VERSION ""

NS_ :

BS_:

BU_: Vector__XXX

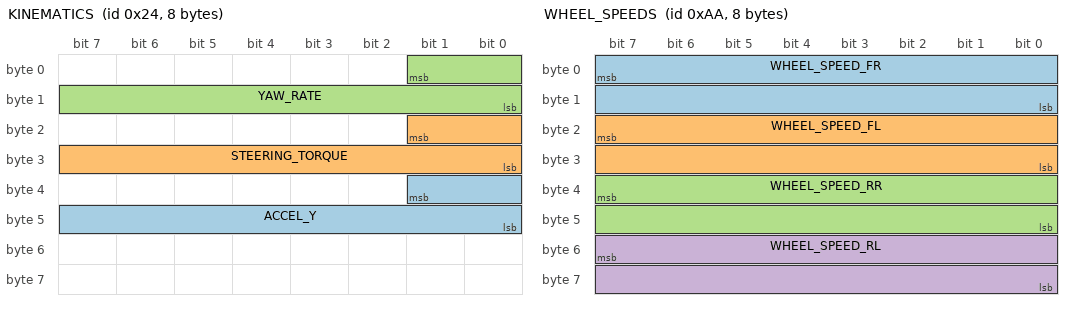
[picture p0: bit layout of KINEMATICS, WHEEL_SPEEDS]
BO_ 36 KINEMATICS: 8 Vector__XXX
SG_ ACCEL_Y : 33|10@0+ (1,-512) [0|511] "" Vector__XXX
SG_ STEERING_TORQUE : 17|10@0+ (1,-512) [0|511] "" Vector__XXX
SG_ YAW_RATE : 1|10@0+ (1,-512) [0|511] "" Vector__XXX

BO_ 166 BRAKE: 8 Vector__XXX
SG_ BRAKE_AMOUNT : 7|8@0+ (1,0) [0|255] "" Vector__XXX
SG_ BRAKE_PEDAL : 23|8@0+ (1,0) [0|255] "" Vector__XXX

BO_ 170 WHEEL_SPEEDS: 8 Vector__XXX
SG_ WHEEL_SPEED_FR : 7|16@0+ (0.0062,-67.67) [0|250] "mph" Vector__XXX
SG_ WHEEL_SPEED_FL : 23|16@0+ (0.0062,-67.67) [0|250] "mph" Vector__XXX
SG_ WHEEL_SPEED_RR : 39|16@0+ (0.0062,-67.67) [0|250] "mph" Vector__XXX
SG_ WHEEL_SPEED_RL : 55|16@0+ (0.0062,-67.67) [0|250] "mph" Vector__XXX

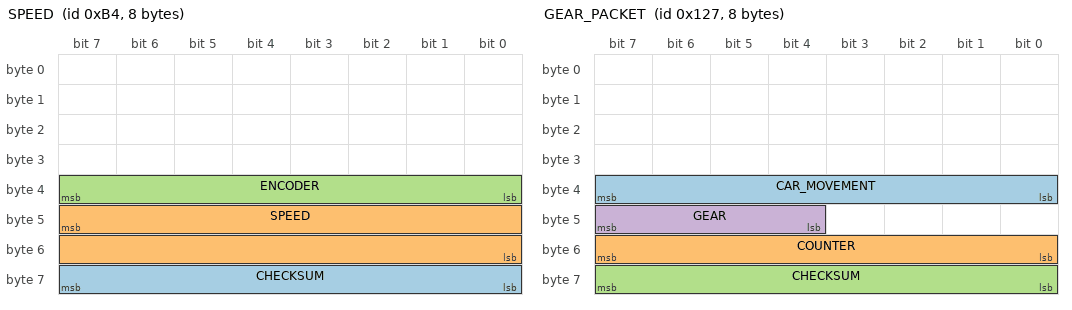
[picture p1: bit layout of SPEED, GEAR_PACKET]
BO_ 180 SPEED: 8 Vector__XXX
SG_ CHECKSUM : 63|8@0+ (1,0) [0|255] "" Vector__XXX
SG_ SPEED : 47|16@0+ (0.0062,0) [0|115] "mph" Vector__XXX
SG_ ENCODER : 39|8@0+ (1,0) [0|255] "" Vector__XXX

BO_ 295 GEAR_PACKET: 8 Vector__XXX
SG_ CAR_MOVEMENT : 39|8@0- (1,0) [0|127] "" Vector__XXX
SG_ COUNTER : 55|8@0+ (1,0) [0|255] "" Vector__XXX
SG_ CHECKSUM : 63|8@0+ (1,0) [0|255] "" Vector__XXX
SG_ GEAR : 47|4@0+ (1,0) [0|15] "" Vector__XXX

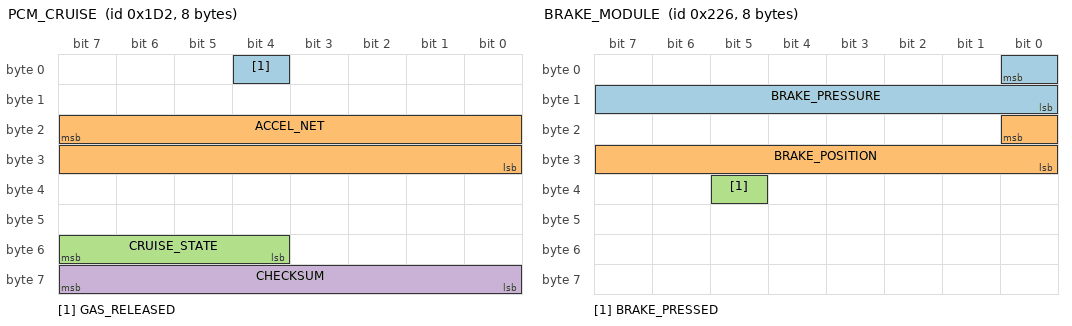
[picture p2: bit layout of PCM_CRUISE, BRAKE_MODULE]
BO_ 466 PCM_CRUISE: 8 Vector__XXX
SG_ GAS_RELEASED : 4|1@0+ (1,0) [0|1] "" Vector__XXX
SG_ ACCEL_NET : 23|16@0- (0.001,0) [-20|20] "m/s2" Vector__XXX
SG_ CRUISE_STATE : 55|4@0+ (1,0) [0|15] "" Vector__XXX
SG_ CHECKSUM : 63|8@0+ (1,0) [0|255] "" Vector__XXX

BO_ 550 BRAKE_MODULE: 8 Vector__XXX
SG_ BRAKE_PRESSURE : 0|9@0+ (1,0) [0|511] "" Vector__XXX
SG_ BRAKE_POSITION : 16|9@0+ (1,0) [0|511] "" Vector__XXX
SG_ BRAKE_PRESSED : 37|1@0+ (1,0) [0|1] "" Vector__XXX

BO_ 552 ACCELEROMETER: 8 Vector__XXX
SG_ ACCEL_Z : 22|15@0- (1,0) [0|16383] "" Vector__XXX
SG_ ACCEL_X : 6|15@0- (0.001,0) [-16.384|16.383] "m/s2" Vector__XXX

BO_ 560 BRAKE_MODULE2: 8 Vector__XXX
SG_ BRAKE_LIGHTS : 26|1@0+ (1,0) [0|1] "" Vector__XXX

BO_ 581 GAS_PEDAL: 8 Vector__XXX
SG_ GAS_PEDAL : 23|8@0+ (0.005,0) [0|1] "" Vector__XXX

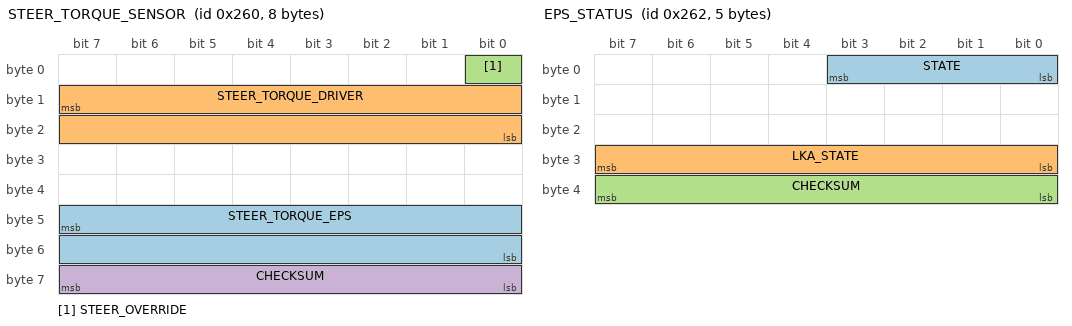
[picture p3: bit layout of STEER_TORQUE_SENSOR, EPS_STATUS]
BO_ 608 STEER_TORQUE_SENSOR: 8 Vector__XXX
SG_ STEER_TORQUE_EPS : 47|16@0- (0.66,0) [-20000|20000] "" Vector__XXX
SG_ STEER_TORQUE_DRIVER : 15|16@0- (1,0) [-32768|32767] "" Vector__XXX
SG_ STEER_OVERRIDE : 0|1@0+ (1,0) [0|1] "" Vector__XXX
SG_ CHECKSUM : 63|8@0+ (1,0) [0|255] "" Vector__XXX

BO_ 610 EPS_STATUS: 5 Vector__XXX
SG_ STATE : 3|4@0+ (1,0) [0|15] "" Vector__XXX
SG_ LKA_STATE : 31|8@0+ (1,0) [0|255] "" Vector__XXX
SG_ CHECKSUM : 39|8@0+ (1,0) [0|255] "" Vector__XXX

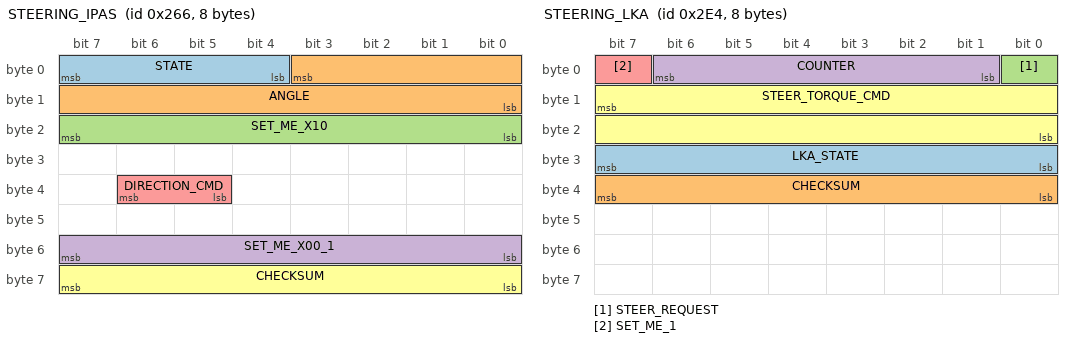
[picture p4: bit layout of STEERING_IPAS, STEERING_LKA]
BO_ 614 STEERING_IPAS: 8 Vector__XXX
SG_ STATE : 7|4@0+ (1,0) [0|15] "" Vector__XXX
SG_ ANGLE : 3|12@0- (1,0) [0|2047] "" Vector__XXX
SG_ SET_ME_X10 : 23|8@0+ (1,0) [0|255] "" Vector__XXX
SG_ SET_ME_X00_1 : 55|8@0+ (1,0) [0|255] "" Vector__XXX
SG_ DIRECTION_CMD : 38|2@0+ (1,0) [0|3] "" Vector__XXX
SG_ CHECKSUM : 63|8@0+ (1,0) [0|255] "" Vector__XXX

BO_ 643 PRE_COLLISION: 8 Vector__XXX

BO_ 740 STEERING_LKA: 8 Vector__XXX
SG_ LKA_STATE : 31|8@0+ (1,0) [0|255] "" Vector__XXX
SG_ CHECKSUM : 39|8@0+ (1,0) [0|255] "" Vector__XXX
SG_ STEER_REQUEST : 0|1@0+ (1,0) [0|1] "" Vector__XXX
SG_ COUNTER : 6|6@0+ (1,0) [0|63] "" Vector__XXX
SG_ SET_ME_1 : 7|1@0+ (1,0) [0|1] "" Vector__XXX
SG_ STEER_TORQUE_CMD : 15|16@0- (1,0) [0|32767] "" Vector__XXX

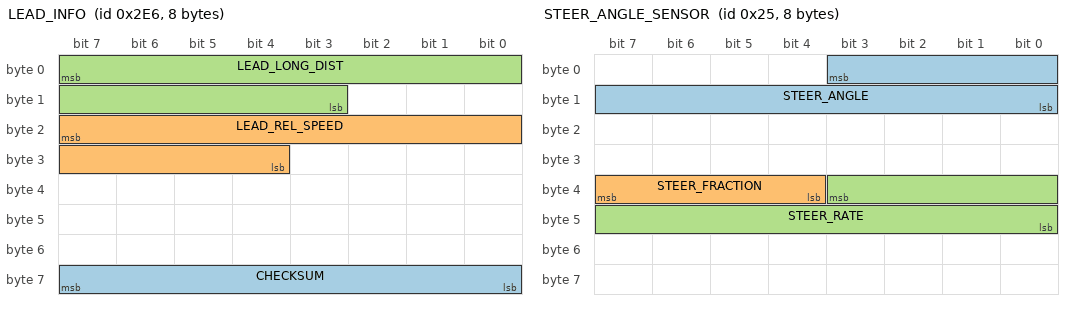
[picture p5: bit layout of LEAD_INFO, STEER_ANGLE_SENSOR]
BO_ 742 LEAD_INFO: 8 Vector__XXX
SG_ CHECKSUM : 63|8@0+ (1,0) [0|255] "" Vector__XXX
SG_ LEAD_REL_SPEED : 23|12@0- (0.025,0) [-51.2|51.175] "m/s" Vector__XXX
SG_ LEAD_LONG_DIST : 7|13@0+ (0.05,0) [0|300] "m" Vector__XXX

BO_ 835 ACC_CONTROL: 8 Vector__XXX
SG_ ACCEL_CMD : 7|16@0- (0.001,0) [-20|20] "m/s2" Vector__XXX

BO_ 1556 STEERING_LEVERS: 8 Vector__XXX
SG_ TURN_SIGNALS : 29|2@0+ (1,0) [0|3] "" Vector__XXX

BO_ 37 STEER_ANGLE_SENSOR: 8 Vector__XXX
SG_ STEER_ANGLE : 3|12@0- (1.5,0) [-500|500] "deg" Vector__XXX
SG_ STEER_FRACTION : 39|4@0- (0.1,0) [-0.7|0.7] "deg" Vector__XXX
SG_ STEER_RATE : 35|12@0- (1,0) [-2000|2000] "deg/s" Vector__XXX

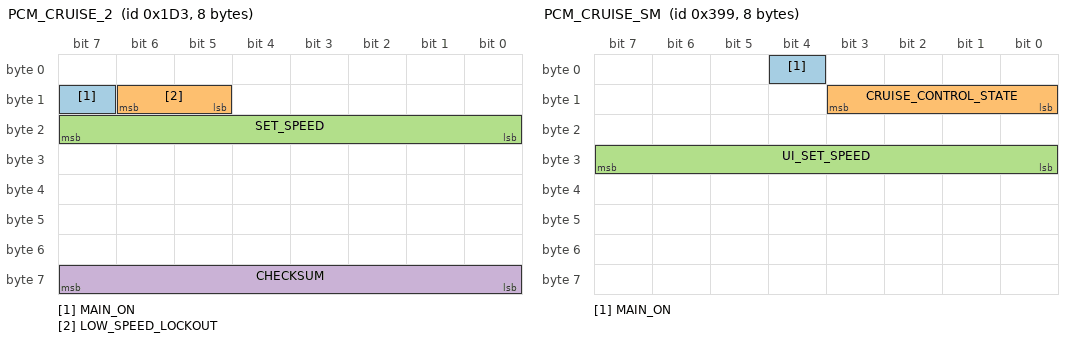
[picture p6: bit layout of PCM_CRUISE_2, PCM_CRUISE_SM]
BO_ 467 PCM_CRUISE_2: 8 Vector__XXX
SG_ MAIN_ON : 15|1@0+ (1,0) [0|1] "" Vector__XXX
SG_ LOW_SPEED_LOCKOUT : 14|2@0+ (1,0) [0|3] "kph" Vector__XXX
SG_ SET_SPEED : 23|8@0+ (1,0) [0|255] "kph" Vector__XXX
SG_ CHECKSUM : 63|8@0+ (1,0) [0|255] "" Vector__XXX

BO_ 921 PCM_CRUISE_SM: 8 Vector__XXX
SG_ MAIN_ON : 4|1@0+ (1,0) [0|1] "" Vector__XXX
SG_ CRUISE_CONTROL_STATE : 11|4@0+ (1,0) [0|15] "" Vector__XXX
SG_ UI_SET_SPEED : 31|8@0+ (1,0) [0|255] "" Vector__XXX

BO_ 951 ESP_CONTROL: 8 Vector__XXX
SG_ TC_DISABLED : 13|1@0+ (1,0) [0|1] "" Vector__XXX

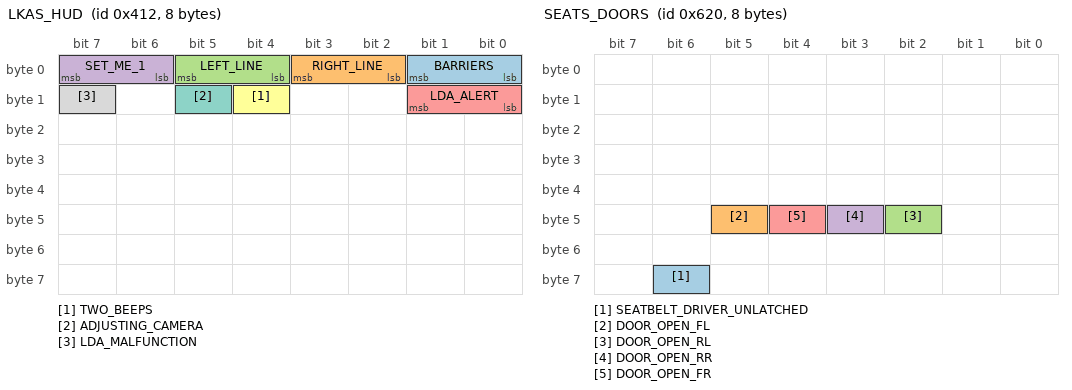
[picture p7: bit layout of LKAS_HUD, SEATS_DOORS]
BO_ 1042 LKAS_HUD: 8 Vector__XXX
SG_ BARRIERS : 1|2@0+ (1,0) [0|3] "" Vector__XXX
SG_ RIGHT_LINE : 3|2@0+ (1,0) [0|3] "" Vector__XXX
SG_ LEFT_LINE : 5|2@0+ (1,0) [0|3] "" Vector__XXX
SG_ SET_ME_1 : 7|2@0+ (1,0) [0|3] "" Vector__XXX
SG_ LDA_ALERT : 9|2@0+ (1,0) [0|3] "" Vector__XXX
SG_ TWO_BEEPS : 12|1@0+ (1,0) [0|1] "" Vector__XXX
SG_ ADJUSTING_CAMERA : 13|1@0+ (1,0) [0|1] "" Vector__XXX
SG_ LDA_MALFUNCTION : 15|1@0+ (1,0) [0|1] "" Vector__XXX

BO_ 1553 UI_SEETING: 8 Vector__XXX
SG_ UNITS : 26|2@0+ (1,0) [0|3] "" Vector__XXX

BO_ 1568 SEATS_DOORS: 8 Vector__XXX
SG_ SEATBELT_DRIVER_UNLATCHED : 62|1@0+ (1,0) [0|1] "" Vector__XXX
SG_ DOOR_OPEN_FL : 45|1@0+ (1,0) [0|1] "" Vector__XXX
SG_ DOOR_OPEN_RL : 42|1@0+ (1,0) [0|1] "" Vector__XXX
SG_ DOOR_OPEN_RR : 43|1@0+ (1,0) [0|1] "" Vector__XXX
SG_ DOOR_OPEN_FR : 44|1@0+ (1,0) [0|1] "" Vector__XXX

BO_ 452 POWERTRAIN: 8 Vector__XXX
SG_ ENGINE_RPM : 7|16@0+ (1,0) [0|65535] "rpm" Vector__XXX
SG_ CHECKSUM : 63|8@0+ (1,0) [0|255] "" Vector__XXX

CM_ SG_ 36 ACCEL_Y "unit is tbd";
CM_ SG_ 36 STEERING_TORQUE "does not seem the steer torque, tbd";
CM_ SG_ 36 YAW_RATE "verify";
CM_ SG_ 466 ACCEL_NET "net acceleration produced by the system, given ACCEL_CMD, road grade and other factors";
CM_ SG_ 466 CRUISE_STATE "Active state is 8, if standstill is requested will switch to state 11(3 sec timer), after timer is elapsed will switch into state 7(standstill). If plus button was pressed - status 9, minus button pressed - status 10";
CM_ SG_ 550 BRAKE_PRESSURE "seems prop to pedal force";
CM_ SG_ 550 BRAKE_POSITION "seems proportional to pedal displacement, unclear the max value of 0x1c8";
CM_ SG_ 560 BRAKE_LIGHTS "double check";
CM_ SG_ 581 GAS_PEDAL "it seems slightly filtered";
CM_ SG_ 608 STEER_TORQUE_DRIVER "driver torque";
CM_ SG_ 608 STEER_OVERRIDE "set when driver torque exceeds a certain value";
CM_ SG_ 614 ANGLE "set to measured angle when ipas control isn't active";
CM_ SG_ 37 STEER_FRACTION "1/15th of the signal STEER_ANGLE, which is 1.5 deg; note that 0x8 is never set";
CM_ SG_ 37 STEER_RATE "factor is tbd";
CM_ SG_ 467 LOW_SPEED_LOCKOUT "in low speed lockout, system would always disengage below 28mph";
CM_ SG_ 467 SET_SPEED "43 kph are shown as 28mph, so conversion isn't perfect";
CM_ SG_ 921 UI_SET_SPEED "set speed shown in UI with user set unit";
CM_ SG_ 1042 SET_ME_1 "unclear what this is, nut it's always 1 in drive traces";

BA_DEF_  "BusType" STRING ;

BA_DEF_DEF_  "BusType" "CAN";

VAL_ 295 GEAR 0 "P" 1 "R" 2 "N" 3 "D" 4 "B";
VAL_ 466 CRUISE_STATE 11 "timer_3sec" 10 "setspeeddown" 9 "setspeedup" 8 "active" 7 "standstill" 1 "off" 0 "off";
VAL_ 610 STATE 5 "override" 3 "enabled" 1 "disabled";
VAL_ 610 LKA_STATE 50 "temporary_fault";
VAL_ 614 STATE 3 "enabled" 1 "disabled";
VAL_ 614 DIRECTION_CMD 3 "right" 2 "center" 1 "left";
VAL_ 1556 TURN_SIGNALS 3 "none" 2 "right" 1 "left";
VAL_ 467 LOW_SPEED_LOCKOUT 2 "low speed locked" 1 "ok";
VAL_ 921 CRUISE_CONTROL_STATE 2 "disabled" 11 "hold" 10 "hold_waiting_user_cmd" 6 "enabled" 5 "faulted";
VAL_ 1042 BARRIERS 3 "both" 2 "right" 1 "left" 0 "none";
VAL_ 1042 RIGHT_LINE 3 "orange" 2 "double" 1 "solid" 0 "none";
VAL_ 1042 LEFT_LINE 3 "orange" 2 "double" 1 "solid" 0 "none";
VAL_ 1042 LDA_ALERT 3 "hold with continuous beep" 2 "LDA unavailable" 1 "hold" 0 "none";
VAL_ 1553 UNITS 1 "km" 2 "miles";
